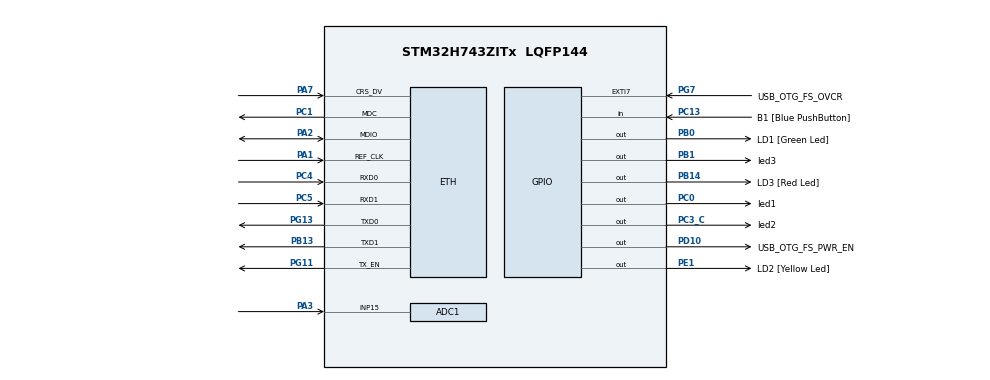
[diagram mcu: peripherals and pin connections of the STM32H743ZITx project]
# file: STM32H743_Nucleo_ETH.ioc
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ADC1.Channel-4\#ChannelRegularConversion=ADC_CHANNEL_15
ADC1.NbrOfConversionFlag=1
ADC1.OffsetNumber-4\#ChannelRegularConversion=ADC_OFFSET_NONE
ADC1.OffsetSignedSaturation-4\#ChannelRegularConversion=DISABLE
ADC1.Rank-4\#ChannelRegularConversion=1
ADC1.SamplingTime-4\#ChannelRegularConversion=ADC_SAMPLETIME_1CYCLE_5
ADC1.master=1
CORTEX_M7.AccessPermission_S-Cortex_Memory_Protection_Unit_Region1_Settings_S=MPU_REGION_FULL_ACCESS
CORTEX_M7.AccessPermission_S-Cortex_Memory_Protection_Unit_Region2_Settings_S=MPU_REGION_FULL_ACCESS
CORTEX_M7.BaseAddress_S-Cortex_Memory_Protection_Unit_Region1_Settings_S=0x30020000
CORTEX_M7.BaseAddress_S-Cortex_Memory_Protection_Unit_Region2_Settings_S=0x30040000
CORTEX_M7.CPU_DCache=Enabled
CORTEX_M7.CPU_ICache=Enabled
CORTEX_M7.DisableExec_S-Cortex_Memory_Protection_Unit_Region1_Settings_S=MPU_INSTRUCTION_ACCESS_DISABLE
CORTEX_M7.DisableExec_S-Cortex_Memory_Protection_Unit_Region2_Settings_S=MPU_INSTRUCTION_ACCESS_DISABLE
CORTEX_M7.Enable_S-Cortex_Memory_Protection_Unit_Region1_Settings_S=MPU_REGION_ENABLE
CORTEX_M7.Enable_S-Cortex_Memory_Protection_Unit_Region2_Settings_S=MPU_REGION_ENABLE
CORTEX_M7.IsBufferable_S-Cortex_Memory_Protection_Unit_Region2_Settings_S=MPU_ACCESS_BUFFERABLE
CORTEX_M7.IsShareable_S-Cortex_Memory_Protection_Unit_Region2_Settings_S=MPU_ACCESS_SHAREABLE
CORTEX_M7.Size_S-Cortex_Memory_Protection_Unit_Region1_Settings_S=MPU_REGION_SIZE_128KB
CORTEX_M7.Size_S-Cortex_Memory_Protection_Unit_Region2_Settings_S=MPU_REGION_SIZE_512B
CORTEX_M7.TypeExtField_S-Cortex_Memory_Protection_Unit_Region1_Settings_S=MPU_TEX_LEVEL1
CORTEX_M7.default_mode_Activation=1
ETH.MediaInterface=HAL_ETH_RMII_MODE
ETH.RxBuffLen=1536
ETH.RxDescAddress=0x30040000
ETH.TxDescAddress=0x30040200
FREERTOS.Tasks01=defaultTask,24,512,StartDefaultTask,Default,NULL,Dynamic,NULL,NULL
FREERTOS.configUSE_NEWLIB_REENTRANT=1
LWIP.BSP.number=1
LWIP.DEFAULT_THREAD_STACKSIZE=2048
LWIP.GATEWAY_ADDRESS=192.168.000.001
LWIP.IP_ADDRESS=192.168.000.010
LWIP.LWIP_DHCP=0
LWIP.LWIP_RAM_HEAP_POINTER=0x30020000
LWIP.MEM_SIZE=131048
LWIP.NETMASK_ADDRESS=255.255.255.000
LWIP.PBUF_POOL_BUFSIZE=592
LWIP.TCPIP_THREAD_STACKSIZE=2048
LWIP.TCP_MSS=1460
LWIP.TCP_SND_BUF=5840
LWIP.TCP_SND_QUEUELEN=16
LWIP.Version=v2.1.2_Cube
LWIP0.BSP.STBoard=false
LWIP0.BSP.api=BSP_COMPONENT_DRIVER
LWIP0.BSP.component=LAN8742
LWIP0.BSP.instance=LAN8742
LWIP0.BSP.name=Driver_PHY
LWIP0.BSP.semaphore=S_LAN8742
LWIP0.BSP.solution=LAN8742
Mcu.Family=STM32H7
Mcu.Name=STM32H743ZITx
Mcu.Package=LQFP144
NVIC.ETH_IRQn=true\:5\:0\:false\:false\:true\:true\:true\:true\:true
NVIC.PriorityGroup=NVIC_PRIORITYGROUP_4
NVIC.TIM6_DAC_IRQn=true\:1\:0\:true\:false\:true\:false\:false\:true\:true
NVIC.TimeBase=TIM6_DAC_IRQn
NVIC.TimeBaseIP=TIM6
PA1.GPIO_Speed=GPIO_SPEED_FREQ_VERY_HIGH
PA1.Mode=RMII
PA1.Signal=ETH_REF_CLK
PA11.Signal=USB_OTG_FS_DM
PA12.Signal=USB_OTG_FS_DP
PA2.GPIO_Speed=GPIO_SPEED_FREQ_VERY_HIGH
PA2.Mode=RMII
PA2.Signal=ETH_MDIO
PA3.Signal=ADCx_INP15
PA7.GPIO_Speed=GPIO_SPEED_FREQ_VERY_HIGH
PA7.Mode=RMII
PA7.Signal=ETH_CRS_DV
PA8.Signal=USB_OTG_FS_SOF
PA9.Signal=USB_OTG_FS_VBUS
PB0.GPIO_Label=LD1 [Green Led]
PB0.Signal=GPIO_Output
PB1.GPIO_Label=led3
PB1.Signal=GPIO_Output
PB13.GPIO_Speed=GPIO_SPEED_FREQ_VERY_HIGH
PB13.Mode=RMII
PB13.Signal=ETH_TXD1
PB14.GPIO_Label=LD3 [Red Led]
PB14.Signal=GPIO_Output
PC0.GPIO_Label=led1
PC0.Signal=GPIO_Output
PC1.GPIO_Speed=GPIO_SPEED_FREQ_VERY_HIGH
PC1.Mode=RMII
PC1.Signal=ETH_MDC
PC13.GPIO_Label=B1 [Blue PushButton]
PC13.Signal=GPIO_Input
PC14-OSC32_IN\ (OSC32_IN).Signal=RCC_OSC32_IN
PC15-OSC32_OUT\ (OSC32_OUT).Signal=RCC_OSC32_OUT
PC3_C.GPIO_Label=led2
PC3_C.Signal=GPIO_Output
PC4.GPIO_Speed=GPIO_SPEED_FREQ_VERY_HIGH
PC4.Mode=RMII
PC4.Signal=ETH_RXD0
PC5.GPIO_Speed=GPIO_SPEED_FREQ_VERY_HIGH
PC5.Mode=RMII
PC5.Signal=ETH_RXD1
PD10.GPIO_Label=USB_OTG_FS_PWR_EN
PD10.Signal=GPIO_Output
PD8.GPIO_Label=STLINK_RX
PD8.Signal=USART3_TX
PD9.GPIO_Label=STLINK_TX
PD9.Signal=USART3_RX
PE1.GPIO_Label=LD2 [Yellow Led]
PE1.Signal=GPIO_Output
PG11.GPIO_Speed=GPIO_SPEED_FREQ_VERY_HIGH
PG11.Mode=RMII
PG11.Signal=ETH_TX_EN
PG13.GPIO_Speed=GPIO_SPEED_FREQ_VERY_HIGH
PG13.Mode=RMII
PG13.Signal=ETH_TXD0
PG7.GPIO_Label=USB_OTG_FS_OVCR
PG7.Signal=GPXTI7
PH0-OSC_IN\ (PH0).Mode=HSE-External-Clock-Source
PH0-OSC_IN\ (PH0).Signal=RCC_OSC_IN
PH1-OSC_OUT\ (PH1).Signal=RCC_OSC_OUT
ProjectManager.HeapSize=0x200
ProjectManager.StackSize=0x400
ProjectManager.TargetToolchain=STM32CubeIDE
RCC.ADCFreq_Value=80000000
RCC.APB1Freq_Value=120000000
RCC.APB2Freq_Value=120000000
RCC.APB3Freq_Value=120000000
RCC.APB4Freq_Value=120000000
RCC.CortexFreq_Value=480000000
RCC.D1PPRE=RCC_APB3_DIV2
RCC.D2PPRE1=RCC_APB1_DIV2
RCC.D2PPRE2=RCC_APB2_DIV2
RCC.D3PPRE=RCC_APB4_DIV2
RCC.DIVM1=4
RCC.DIVM2=4
RCC.DIVN1=60
RCC.DIVN2=10
RCC.HCLKFreq_Value=240000000
RCC.HPRE=RCC_HCLK_DIV2
RCC.PLL2FRACN=0
RCC.PLLFRACN=0
RCC.SYSCLKFreq_VALUE=480000000
RCC.SYSCLKSource=RCC_SYSCLKSOURCE_PLLCLK
RCC.USBFreq_Value=480000000
SH.ADCx_INP15.0=ADC1_INP15,IN15-Single-Ended
TIM3.AutoReloadPreload=TIM_AUTORELOAD_PRELOAD_ENABLE
TIM3.Period=1000
TIM3.Prescaler=24000
VP_FREERTOS_VS_CMSIS_V2.Mode=CMSIS_V2
VP_LWIP_VS_Enabled.Mode=Enabled
VP_MEMORYMAP_VS_MEMORYMAP.Mode=CurAppReg
VP_SYS_VS_tim6.Mode=TIM6
VP_TIM3_VS_ClockSourceINT.Mode=Internal
board=NUCLEO-H743ZI2

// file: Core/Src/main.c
/* USER CODE BEGIN Header */
/**
  ******************************************************************************
  * @file           : main.c
  * @brief          : Main program body
  ******************************************************************************
  * @attention
  *
  * Copyright (c) 2022 STMicroelectronics.
  * All rights reserved.
  *
  * This software is licensed under terms that can be found in the LICENSE file
  * in the root directory of this software component.
  * If no LICENSE file comes with this software, it is provided AS-IS.
  *
  ******************************************************************************
  */
/* USER CODE END Header */
#include "main.h"
#include "cmsis_os.h"
#include "lwip.h"

/* USER CODE BEGIN Includes */
/* ETH_CODE: add lwiperf, see comment in StartDefaultTask function */
#include "lwip/apps/lwiperf.h"
#include "udp_echoserver.h"
/* USER CODE END Includes */

ADC_HandleTypeDef hadc1;

TIM_HandleTypeDef htim3;

/* Definitions for defaultTask */
osThreadId_t defaultTaskHandle;
const osThreadAttr_t defaultTask_attributes = {
  .name = "defaultTask",
  .stack_size = 512 * 4,
  .priority = (osPriority_t) osPriorityNormal,
};

void SystemClock_Config(void);
static void MPU_Config(void);
static void MX_GPIO_Init(void);
static void MX_ADC1_Init(void);
static void MX_TIM3_Init(void);
void StartDefaultTask(void *argument);

int main(void)
{

  /* MPU Configuration--------------------------------------------------------*/
  MPU_Config();

  /* Enable the CPU Cache */

  /* Enable I-Cache---------------------------------------------------------*/
  SCB_EnableICache();

  /* Enable D-Cache---------------------------------------------------------*/
  SCB_EnableDCache();

  /* MCU Configuration--------------------------------------------------------*/

  /* Reset of all peripherals, Initializes the Flash interface and the Systick. */
  HAL_Init();

  /* Configure the system clock */
  SystemClock_Config();

  /* Initialize all configured peripherals */
  MX_GPIO_Init();
  MX_ADC1_Init();
  MX_TIM3_Init();

  /* Init scheduler */
  osKernelInitialize();

  /* Create the thread(s) */
  /* creation of defaultTask */
  defaultTaskHandle = osThreadNew(StartDefaultTask, NULL, &defaultTask_attributes);

  /* Start scheduler */
  osKernelStart();

  /* We should never get here as control is now taken by the scheduler */

  /* Infinite loop */
  while (1)
  {

  }
}

void SystemClock_Config(void)
{
  RCC_OscInitTypeDef RCC_OscInitStruct = {0};
  RCC_ClkInitTypeDef RCC_ClkInitStruct = {0};

  /** Supply configuration update enable
  */
  HAL_PWREx_ConfigSupply(PWR_LDO_SUPPLY);

  /** Configure the main internal regulator output voltage
  */
  __HAL_PWR_VOLTAGESCALING_CONFIG(PWR_REGULATOR_VOLTAGE_SCALE1);

  while(!__HAL_PWR_GET_FLAG(PWR_FLAG_VOSRDY)) {}

  __HAL_RCC_SYSCFG_CLK_ENABLE();
  __HAL_PWR_VOLTAGESCALING_CONFIG(PWR_REGULATOR_VOLTAGE_SCALE0);

  while(!__HAL_PWR_GET_FLAG(PWR_FLAG_VOSRDY)) {}

  /** Initializes the RCC Oscillators according to the specified parameters
  * in the RCC_OscInitTypeDef structure.
  */
  RCC_OscInitStruct.OscillatorType = RCC_OSCILLATORTYPE_HSI;
  RCC_OscInitStruct.HSIState = RCC_HSI_DIV1;
  RCC_OscInitStruct.HSICalibrationValue = RCC_HSICALIBRATION_DEFAULT;
  RCC_OscInitStruct.PLL.PLLState = RCC_PLL_ON;
  RCC_OscInitStruct.PLL.PLLSource = RCC_PLLSOURCE_HSI;
  RCC_OscInitStruct.PLL.PLLM = 4;
  RCC_OscInitStruct.PLL.PLLN = 60;
  RCC_OscInitStruct.PLL.PLLP = 2;
  RCC_OscInitStruct.PLL.PLLQ = 2;
  RCC_OscInitStruct.PLL.PLLR = 2;
  RCC_OscInitStruct.PLL.PLLRGE = RCC_PLL1VCIRANGE_3;
  RCC_OscInitStruct.PLL.PLLVCOSEL = RCC_PLL1VCOWIDE;
  RCC_OscInitStruct.PLL.PLLFRACN = 0;
  if (HAL_RCC_OscConfig(&RCC_OscInitStruct) != HAL_OK)
  {
    Error_Handler();
  }

  /** Initializes the CPU, AHB and APB buses clocks
  */
  RCC_ClkInitStruct.ClockType = RCC_CLOCKTYPE_HCLK|RCC_CLOCKTYPE_SYSCLK
                              |RCC_CLOCKTYPE_PCLK1|RCC_CLOCKTYPE_PCLK2
                              |RCC_CLOCKTYPE_D3PCLK1|RCC_CLOCKTYPE_D1PCLK1;
  RCC_ClkInitStruct.SYSCLKSource = RCC_SYSCLKSOURCE_PLLCLK;
  RCC_ClkInitStruct.SYSCLKDivider = RCC_SYSCLK_DIV1;
  RCC_ClkInitStruct.AHBCLKDivider = RCC_HCLK_DIV2;
  RCC_ClkInitStruct.APB3CLKDivider = RCC_APB3_DIV2;
  RCC_ClkInitStruct.APB1CLKDivider = RCC_APB1_DIV2;
  RCC_ClkInitStruct.APB2CLKDivider = RCC_APB2_DIV2;
  RCC_ClkInitStruct.APB4CLKDivider = RCC_APB4_DIV2;

  if (HAL_RCC_ClockConfig(&RCC_ClkInitStruct, FLASH_LATENCY_4) != HAL_OK)
  {
    Error_Handler();
  }
}

static void MX_ADC1_Init(void)
{

  ADC_MultiModeTypeDef multimode = {0};
  ADC_ChannelConfTypeDef sConfig = {0};

  /** Common config
  */
  hadc1.Instance = ADC1;
  hadc1.Init.ScanConvMode = ADC_SCAN_DISABLE;
  hadc1.Init.EOCSelection = ADC_EOC_SINGLE_CONV;
  hadc1.Init.LowPowerAutoWait = DISABLE;
  hadc1.Init.ContinuousConvMode = DISABLE;
  hadc1.Init.NbrOfConversion = 1;
  hadc1.Init.DiscontinuousConvMode = DISABLE;
  hadc1.Init.ExternalTrigConv = ADC_SOFTWARE_START;
  hadc1.Init.ExternalTrigConvEdge = ADC_EXTERNALTRIGCONVEDGE_NONE;
  hadc1.Init.ConversionDataManagement = ADC_CONVERSIONDATA_DR;
  hadc1.Init.Overrun = ADC_OVR_DATA_PRESERVED;
  hadc1.Init.LeftBitShift = ADC_LEFTBITSHIFT_NONE;
  hadc1.Init.OversamplingMode = DISABLE;
  hadc1.Init.Oversampling.Ratio = 1;
  if (HAL_ADC_Init(&hadc1) != HAL_OK)
  {
    Error_Handler();
  }
  hadc1.Init.ClockPrescaler = ADC_CLOCK_ASYNC_DIV1;
  hadc1.Init.Resolution = ADC_RESOLUTION_16B;
  if (HAL_ADC_Init(&hadc1) != HAL_OK)
  {
    Error_Handler();
  }

  /** Configure the ADC multi-mode
  */
  multimode.Mode = ADC_MODE_INDEPENDENT;
  if (HAL_ADCEx_MultiModeConfigChannel(&hadc1, &multimode) != HAL_OK)
  {
    Error_Handler();
  }

  /** Configure Regular Channel
  */
  sConfig.Channel = ADC_CHANNEL_15;
  sConfig.Rank = ADC_REGULAR_RANK_1;
  sConfig.SamplingTime = ADC_SAMPLETIME_1CYCLE_5;
  sConfig.SingleDiff = ADC_SINGLE_ENDED;
  sConfig.OffsetNumber = ADC_OFFSET_NONE;
  sConfig.Offset = 0;
  sConfig.OffsetSignedSaturation = DISABLE;
  if (HAL_ADC_ConfigChannel(&hadc1, &sConfig) != HAL_OK)
  {
    Error_Handler();
  }

}

static void MX_TIM3_Init(void)
{

  TIM_ClockConfigTypeDef sClockSourceConfig = {0};
  TIM_MasterConfigTypeDef sMasterConfig = {0};

  htim3.Instance = TIM3;
  htim3.Init.Prescaler = 24000;
  htim3.Init.CounterMode = TIM_COUNTERMODE_UP;
  htim3.Init.Period = 1000;
  htim3.Init.ClockDivision = TIM_CLOCKDIVISION_DIV1;
  htim3.Init.AutoReloadPreload = TIM_AUTORELOAD_PRELOAD_ENABLE;
  if (HAL_TIM_Base_Init(&htim3) != HAL_OK)
  {
    Error_Handler();
  }
  sClockSourceConfig.ClockSource = TIM_CLOCKSOURCE_INTERNAL;
  if (HAL_TIM_ConfigClockSource(&htim3, &sClockSourceConfig) != HAL_OK)
  {
    Error_Handler();
  }
  sMasterConfig.MasterOutputTrigger = TIM_TRGO_RESET;
  sMasterConfig.MasterSlaveMode = TIM_MASTERSLAVEMODE_DISABLE;
  if (HAL_TIMEx_MasterConfigSynchronization(&htim3, &sMasterConfig) != HAL_OK)
  {
    Error_Handler();
  }

}

static void MX_GPIO_Init(void)
{
  GPIO_InitTypeDef GPIO_InitStruct = {0};

  /* GPIO Ports Clock Enable */
  __HAL_RCC_GPIOC_CLK_ENABLE();
  __HAL_RCC_GPIOH_CLK_ENABLE();
  __HAL_RCC_GPIOA_CLK_ENABLE();
  __HAL_RCC_GPIOB_CLK_ENABLE();
  __HAL_RCC_GPIOD_CLK_ENABLE();
  __HAL_RCC_GPIOG_CLK_ENABLE();
  __HAL_RCC_GPIOE_CLK_ENABLE();

  /*Configure GPIO pin Output Level */
  HAL_GPIO_WritePin(GPIOC, led1_Pin|led2_Pin, GPIO_PIN_RESET);

  /*Configure GPIO pin Output Level */
  HAL_GPIO_WritePin(GPIOB, LD1_Pin|led3_Pin|LD3_Pin, GPIO_PIN_RESET);

  /*Configure GPIO pin Output Level */
  HAL_GPIO_WritePin(USB_OTG_FS_PWR_EN_GPIO_Port, USB_OTG_FS_PWR_EN_Pin, GPIO_PIN_RESET);

  /*Configure GPIO pin Output Level */
  HAL_GPIO_WritePin(LD2_GPIO_Port, LD2_Pin, GPIO_PIN_RESET);

  /*Configure GPIO pin : B1_Pin */
  GPIO_InitStruct.Pin = B1_Pin;
  GPIO_InitStruct.Mode = GPIO_MODE_INPUT;
  GPIO_InitStruct.Pull = GPIO_NOPULL;
  HAL_GPIO_Init(B1_GPIO_Port, &GPIO_InitStruct);

  /*Configure GPIO pins : led1_Pin led2_Pin */
  GPIO_InitStruct.Pin = led1_Pin|led2_Pin;
  GPIO_InitStruct.Mode = GPIO_MODE_OUTPUT_PP;
  GPIO_InitStruct.Pull = GPIO_NOPULL;
  GPIO_InitStruct.Speed = GPIO_SPEED_FREQ_LOW;
  HAL_GPIO_Init(GPIOC, &GPIO_InitStruct);

  /*Configure GPIO pins : LD1_Pin led3_Pin LD3_Pin */
  GPIO_InitStruct.Pin = LD1_Pin|led3_Pin|LD3_Pin;
  GPIO_InitStruct.Mode = GPIO_MODE_OUTPUT_PP;
  GPIO_InitStruct.Pull = GPIO_NOPULL;
  GPIO_InitStruct.Speed = GPIO_SPEED_FREQ_LOW;
  HAL_GPIO_Init(GPIOB, &GPIO_InitStruct);

  /*Configure GPIO pins : STLINK_RX_Pin STLINK_TX_Pin */
  GPIO_InitStruct.Pin = STLINK_RX_Pin|STLINK_TX_Pin;
  GPIO_InitStruct.Mode = GPIO_MODE_AF_PP;
  GPIO_InitStruct.Pull = GPIO_NOPULL;
  GPIO_InitStruct.Speed = GPIO_SPEED_FREQ_LOW;
  GPIO_InitStruct.Alternate = GPIO_AF7_USART3;
  HAL_GPIO_Init(GPIOD, &GPIO_InitStruct);

  /*Configure GPIO pin : USB_OTG_FS_PWR_EN_Pin */
  GPIO_InitStruct.Pin = USB_OTG_FS_PWR_EN_Pin;
  GPIO_InitStruct.Mode = GPIO_MODE_OUTPUT_PP;
  GPIO_InitStruct.Pull = GPIO_NOPULL;
  GPIO_InitStruct.Speed = GPIO_SPEED_FREQ_LOW;
  HAL_GPIO_Init(USB_OTG_FS_PWR_EN_GPIO_Port, &GPIO_InitStruct);

  /*Configure GPIO pin : USB_OTG_FS_OVCR_Pin */
  GPIO_InitStruct.Pin = USB_OTG_FS_OVCR_Pin;
  GPIO_InitStruct.Mode = GPIO_MODE_IT_RISING;
  GPIO_InitStruct.Pull = GPIO_NOPULL;
  HAL_GPIO_Init(USB_OTG_FS_OVCR_GPIO_Port, &GPIO_InitStruct);

  /*Configure GPIO pins : PA8 PA11 PA12 */
  GPIO_InitStruct.Pin = GPIO_PIN_8|GPIO_PIN_11|GPIO_PIN_12;
  GPIO_InitStruct.Mode = GPIO_MODE_AF_PP;
  GPIO_InitStruct.Pull = GPIO_NOPULL;
  GPIO_InitStruct.Speed = GPIO_SPEED_FREQ_LOW;
  GPIO_InitStruct.Alternate = GPIO_AF10_OTG1_FS;
  HAL_GPIO_Init(GPIOA, &GPIO_InitStruct);

  /*Configure GPIO pin : LD2_Pin */
  GPIO_InitStruct.Pin = LD2_Pin;
  GPIO_InitStruct.Mode = GPIO_MODE_OUTPUT_PP;
  GPIO_InitStruct.Pull = GPIO_NOPULL;
  GPIO_InitStruct.Speed = GPIO_SPEED_FREQ_LOW;
  HAL_GPIO_Init(LD2_GPIO_Port, &GPIO_InitStruct);

}

void StartDefaultTask(void *argument)
{
  /* init code for LWIP */
  MX_LWIP_Init();
  /* USER CODE BEGIN 5 */

    udp_echoserver_init();

    LOCK_TCPIP_CORE();
    lwiperf_start_tcp_server_default(NULL, NULL);

    ip4_addr_t remote_addr;
    IP4_ADDR(&remote_addr, 192, 168, 1, 10);
    lwiperf_start_tcp_client_default(&remote_addr, NULL, NULL);
    UNLOCK_TCPIP_CORE();

    /* Infinite loop */
    for(;;)
    {

      osDelay(100000);
    }

  /* USER CODE END 5 */
}

 /* MPU Configuration */

void MPU_Config(void)
{
  MPU_Region_InitTypeDef MPU_InitStruct = {0};

  /* Disables the MPU */
  HAL_MPU_Disable();

  /** Initializes and configures the Region and the memory to be protected
  */
  MPU_InitStruct.Enable = MPU_REGION_ENABLE;
  MPU_InitStruct.Number = MPU_REGION_NUMBER0;
  MPU_InitStruct.BaseAddress = 0x0;
  MPU_InitStruct.Size = MPU_REGION_SIZE_4GB;
  MPU_InitStruct.SubRegionDisable = 0x87;
  MPU_InitStruct.TypeExtField = MPU_TEX_LEVEL0;
  MPU_InitStruct.AccessPermission = MPU_REGION_NO_ACCESS;
  MPU_InitStruct.DisableExec = MPU_INSTRUCTION_ACCESS_DISABLE;
  MPU_InitStruct.IsShareable = MPU_ACCESS_SHAREABLE;
  MPU_InitStruct.IsCacheable = MPU_ACCESS_NOT_CACHEABLE;
  MPU_InitStruct.IsBufferable = MPU_ACCESS_NOT_BUFFERABLE;

  HAL_MPU_ConfigRegion(&MPU_InitStruct);

  /** Initializes and configures the Region and the memory to be protected
  */
  MPU_InitStruct.Number = MPU_REGION_NUMBER1;
  MPU_InitStruct.BaseAddress = 0x30020000;
  MPU_InitStruct.Size = MPU_REGION_SIZE_128KB;
  MPU_InitStruct.SubRegionDisable = 0x0;
  MPU_InitStruct.TypeExtField = MPU_TEX_LEVEL1;
  MPU_InitStruct.AccessPermission = MPU_REGION_FULL_ACCESS;
  MPU_InitStruct.IsShareable = MPU_ACCESS_NOT_SHAREABLE;

  HAL_MPU_ConfigRegion(&MPU_InitStruct);

  /** Initializes and configures the Region and the memory to be protected
  */
  MPU_InitStruct.Number = MPU_REGION_NUMBER2;
  MPU_InitStruct.BaseAddress = 0x30040000;
  MPU_InitStruct.Size = MPU_REGION_SIZE_512B;
  MPU_InitStruct.TypeExtField = MPU_TEX_LEVEL0;
  MPU_InitStruct.IsShareable = MPU_ACCESS_SHAREABLE;
  MPU_InitStruct.IsBufferable = MPU_ACCESS_BUFFERABLE;

  HAL_MPU_ConfigRegion(&MPU_InitStruct);
  /* Enables the MPU */
  HAL_MPU_Enable(MPU_PRIVILEGED_DEFAULT);

}

void Error_Handler(void)
{
  __disable_irq();
  while (1)
  {
  }
}
